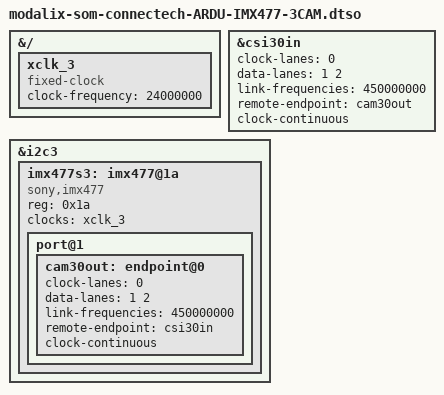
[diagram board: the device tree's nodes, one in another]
// SPDX-License-Identifier: (GPL-2.0+ OR MIT)
/*
 * Copyright (c) 2026 SiMa ai
 */

/dts-v1/;
/plugin/;

#include "modalix-som-connectech-3CAM.dtsi"

&{/} {
        xclk_3: xclk_3 {
                status = "okay";
                compatible = "fixed-clock";
                #clock-cells = <0>;
                clock-frequency = <24000000>;
        };
};

&csi30in {
    clock-lanes = <0>;
    data-lanes = <1 2>;
    link-frequencies = /bits/ 64 <450000000>;
    remote-endpoint = <&cam30out>;
    clock-continuous;
};

&i2c3 {
        imx477s3: imx477@1a {
                compatible = "sony,imx477";
                reg = <0x1a>;

                clocks = <&xclk_3>;
                clock-names = "xclk";

                port@1 {
                        cam30out: endpoint@0 {
                                clock-lanes = <0>;
                                data-lanes = <1 2>;
                                link-frequencies = /bits/ 64 <450000000>;
                                remote-endpoint = <&csi30in>;
                                clock-continuous;
                        };
                };
        };
};
